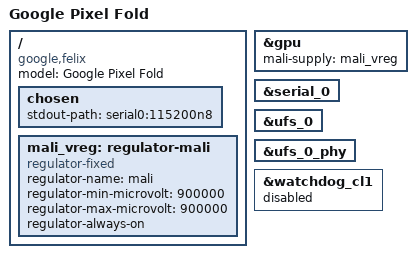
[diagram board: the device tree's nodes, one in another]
// SPDX-License-Identifier: GPL-2.0-only
/*
 * Google Pixel Fold (felix) device tree source
 *
 * Copyright 2026 Google LLC
 *
 * The Pixel Fold uses the GS201 (Tensor G2) SoC.
 *
 * Headless mainline Linux configuration:
 *   - Serial console via UART0 at 115200 baud (earlycon)
 *   - UFS storage via google,gs201-ufs
 *   - USB host via USB 3.1 DWC3 (USB-C port)
 *   - GPU via Panthor (Mali-G710 CSF)
 *
 * Not enabled (no mainline driver or Android-only):
 *   - Display (DRM Samsung DECON + DSI panels)
 *   - Wi-Fi / Bluetooth (Broadcom BCM4390)
 *   - Cellular modem (Samsung S5300)
 *   - Camera (LWIS / ISP)
 *   - Audio (CS35L45, CS40L26)
 *   - NFC, fingerprint, touch
 *   - Google Security Anchor / GSC TPM (GSA/GSC)
 *   - AoC always-on coprocessor
 *   - EdgeTPU / GXP
 */

/dts-v1/;

#include "gs201.dtsi"
#include "gs201-android-handoff.dtsi"

/ {
	model = "Google Pixel Fold";
	compatible = "google,felix", "google,gs201";

	chosen {
		stdout-path = "serial0:115200n8";
	};

	/*
	 * Fixed-regulator stub for the Mali GPU supply. Panthor's probe looks
	 * up a "mali" regulator via devm_regulator_get() to satisfy OPP voltage
	 * scaling and the Energy Model; on felix the GPU is actually fed by an
	 * ACPM-managed rail (BUCK_S2MPG13_3 / VDD_G3D), but there's no driver
	 * for that in this tree yet. A fixed-voltage regulator-always-on stub
	 * satisfies the regulator handle lookup and silences the
	 * "no regulator (mali) found" / "EM: invalid perf. state" errors during
	 * panthor probe. The GPU rail is already powered by the bootloader so
	 * nothing actually changes voltage at runtime.
	 */
	mali_vreg: regulator-mali {
		compatible = "regulator-fixed";
		regulator-name = "mali";
		regulator-min-microvolt = <900000>;
		regulator-max-microvolt = <900000>;
		regulator-always-on;
	};
};

/* Wire the stub regulator to the GPU node as its mali-supply. */
&gpu {
	mali-supply = <&mali_vreg>;
};

/*
 * Debug UART (UART0 / PERIC0 USI0). Enabled (4th attempt).
 *
 * Prior attempts (recorded so the failure modes are easy to spot
 * if any of them recur):
 *   1. samsung_tty as kernel console + fixed-clock stub →
 *      APC-early-watchdog bootloop, kernel hung silently.
 *   2. samsung_tty as platform driver only + 200 MHz fixed-clock
 *      stub → UART garbled at [1.25] when samsung_tty reprogrammed
 *      UBRDIV against a wrong rate.
 *   3. samsung_tty + real cmu_top/cmu_peric0 reusing gs101 driver
 *      data → kernel panic in clk_divider_recalc_rate (mainline
 *      reuses gs101 register offsets which don't all exist on gs201).
 *
 * What's different this time: clk-gs101.c now contains a minimal
 * gs201-specific peric0_cmu_info struct (peric0_cmu_info_gs201)
 * with the gs201 USI0_UART register offsets (DIV at 0x1808 instead
 * of 0x1804, GATE at 0x20c0 instead of 0x20bc). cmu_top stays
 * disabled — cmu_peric0's bus/ip parents come from fixed-clock
 * stubs at the rates AOSP cal-if reports for felix.
 *
 * Safety net: kernel cmdline still keeps `keep_bootcon` and does
 * NOT specify `console=ttySAC0,115200`, so kernel printk continues
 * via earlycon even if samsung_tty's setup against the new
 * cmu_peric0 path goes wrong. /dev/ttySAC0 surfaces only as a
 * platform-driver-bound port (not a kernel console), and
 * serial-getty@ttySAC0 (overlay symlink) opens it for an
 * interactive RX-IRQ-driven shell.
 */
&serial_0 {
	status = "okay";
};

/*
 * Enable UFS storage.
 * The controller and PHY are defined in gs201.dtsi; the GPIO pins used for
 * UFS reset and reference-clock output are PERIC0 / HSI2UFS domain pins.
 */
&ufs_0 {
	status = "okay";
};

&ufs_0_phy {
	status = "okay";
};

/* watchdog_cl1 stays disabled: the s3c2410-wdt of_match table maps
 * google,gs201-wdt → drv_data_gs101_cl0 only, so cl1 would inherit
 * cluster-0 PMU register offsets. */
&watchdog_cl1 {
	status = "disabled";
};

